# STM32F334x register map
File version: 1.0
Registers are 32-bit, read-write, reset 0x0 unless marked. A register's access mark holds for its fields unless they carry their own. Offsets are from the block's base; [hi:lo] are bit positions; {n}, {i} and the like mark numbered series; 'fields as' and 'values as' point back to an identical list.

## HRTIM_TIMA — High Resolution Timer: TIMA
Base 0x40017480
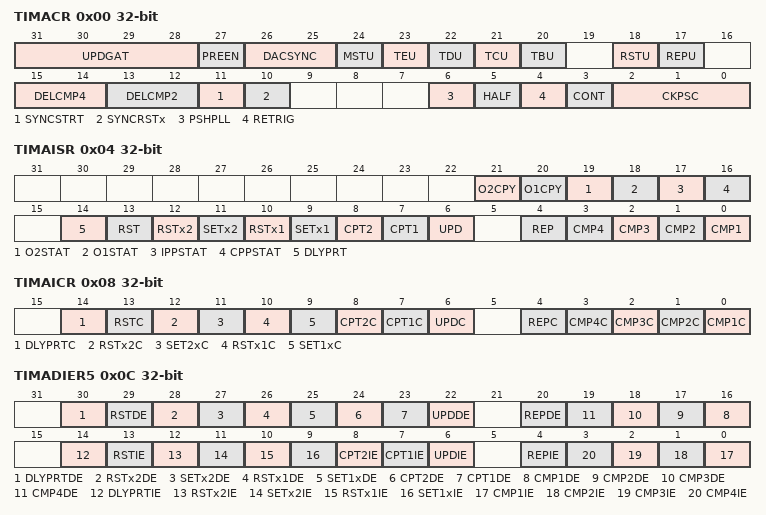
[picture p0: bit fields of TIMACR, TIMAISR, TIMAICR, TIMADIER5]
0x00 TIMACR — Timerx Control Register
  [31:28] UPDGAT — Update Gating
    0=Independent (the update occurs independently from the DMA burst transfer); 1=DMA_Completed (the update occurs when the DMA burst transfer is completed); 2=DMA_Update_Event (the update occurs on the update event following the DMA burst transfer completion); 3=Enable_1 (the update occurs on a rising edge of HRTIM update enable input 1); 4=Enable_2 (the update occurs on a rising edge of HRTIM update enable input 2); 5=Enable_3 (the update occurs on a rising edge of HRTIM update enable input 3); 6=Enable_1_Update_Event (the update occurs on the update event following a rising edge of HRTIM update enable input 1); 7=Enable_2_Update_Event (the update occurs on the update event following a rising edge of HRTIM update enable input 2); 8=Enable_3_Update_Event (the update occurs on the update event following a rising edge of HRTIM update enable input 3)
  [27] PREEN — Preload enable
  [26:25] DACSYNC — DAC Synchronization
    0=None (No update generated); 1=DACtrigOut1 (Update generated on DACtrigOut1); 2=DACtrigOut2 (Update generated on DACtrigOut2); 3=DACtrigOut3 (Update generated on DACtrigOut3)
  [24] MSTU — Master Timer update
  [23] TEU
  [22] TDU
  [21] TCU
  [20] TBU
  [18] RSTU — Timerx reset update
  [17] REPU — Timer x Repetition update
  [15:14] DELCMP4 — CMP4 auto-delayed mode
    0=Always_Active (CMP4 register is always active (standard compare mode)); 1=Capture_2 (CMP4 value is recomputed and is active following a capture 2 event); 2=Capture_2_Or_Compare_1 (CMP4 value is recomputed and is active following a capture 2 event, or is recomputed and active after Compare 1 match (timeout function if capture 2 event is missing)); 3=Capture_2_Or_Compare_3 (CMP4 value is recomputed and is active following a capture event, or is recomputed and active after Compare 3 match (timeout function if capture event is missing))
  [13:12] DELCMP2 — Delayed CMP2 mode
    0=Always_Active (CMP4 register is always active (standard compare mode)); 1=Capture_1 (CMP2 value is recomputed and is active following a capture 1 event); 2=Capture_1_Or_Compare_1 (CMP2 value is recomputed and is active following a capture 1 event, or is recomputed and active after Compare 1 match (timeout function if capture event is missing)); 3=Capture_1_Or_Compare_3 (CMP2 value is recomputed and is active following a capture 1 event, or is recomputed and active after Compare 3 match (timeout function if capture event is missing))
  [11] SYNCSTRT — Synchronization Starts Timer x
  [10] SYNCRSTx — Synchronization Resets Timer x
  [6] PSHPLL — Push-Pull mode enable
  [5] HALF — Half mode enable
  [4] RETRIG — Re-triggerable mode
  [3] CONT — Continuous mode
  [2:0] CKPSC — HRTIM Timer x Clock prescaler
0x04 TIMAISR ro — TimerA Interrupt Status Register
  [21] O2CPY — Output 2 Copy
  [20] O1CPY — Output 1 Copy
  [19] O2STAT — Output 2 State
  [18] O1STAT — Output 1 State
  [17] IPPSTAT — Idle Push Pull Status
  [16] CPPSTAT — Current Push Pull Status
  [14] DLYPRT — Delayed Protection Flag
  [13] RST — Reset Interrupt Flag
  [12] RSTx2 — Output 2 Reset Interrupt Flag
  [11] SETx2 — Output 2 Set Interrupt Flag
  [10] RSTx1 — Output 1 Reset Interrupt Flag
  [9] SETx1 — Output 1 Set Interrupt Flag
  [8] CPT2 — Capture2 Interrupt Flag
  [7] CPT1 — Capture1 Interrupt Flag
  [6] UPD — Update Interrupt Flag
  [4] REP — Repetition Interrupt Flag
  [n-1] CMP{n} (n=1..4) — Compare {n} Interrupt Flag
0x08 TIMAICR wo — Timerx Interrupt Clear Register
  [14] DLYPRTC — Delayed Protection Flag Clear
  [13] RSTC — Reset Interrupt flag Clear
  [12] RSTx2C — Output 2 Reset flag Clear
  [11] SET2xC — Output 2 Set flag Clear
  [10] RSTx1C — Output 1 Reset flag Clear
  [9] SET1xC — Output 1 Set flag Clear
  [8] CPT2C — Capture2 Interrupt flag Clear
  [7] CPT1C — Capture1 Interrupt flag Clear
  [6] UPDC — Update Interrupt flag Clear
  [4] REPC — Repetition Interrupt flag Clear
  [n-1] CMP{n}C (n=1..4) — Compare {n} Interrupt flag Clear
0x0C TIMADIER5 — TIMxDIER5
  [30] DLYPRTDE, [29] RSTDE, [28] RSTx2DE, [27] SETx2DE, [26] RSTx1DE, [25] SET1xDE, [24] CPT2DE, [23] CPT1DE, [22] UPDDE, [20] REPDE, [n+15] CMP{n}DE (n=1..4), [14] DLYPRTIE, [13] RSTIE, [12] RSTx2IE, [11] SETx2IE, [10] RSTx1IE, [9] SET1xIE, [8] CPT2IE, [7] CPT1IE, [6] UPDIE, [4] REPIE, [n-1] CMP{n}IE (n=1..4)
0x10 CNTAR — Timerx Counter Register
  [15:0] CNTx — Timerx Counter value
0x14 PERAR reset 0xFFFF — Timerx Period Register
  [15:0] PERx — Timerx Period value
0x18 REPAR — Timerx Repetition Register
  [7:0] REPx — Timerx Repetition counter value
0x1C CMP1AR — Timerx Compare 1 Register
  [15:0] CMP1x — Timerx Compare 1 value
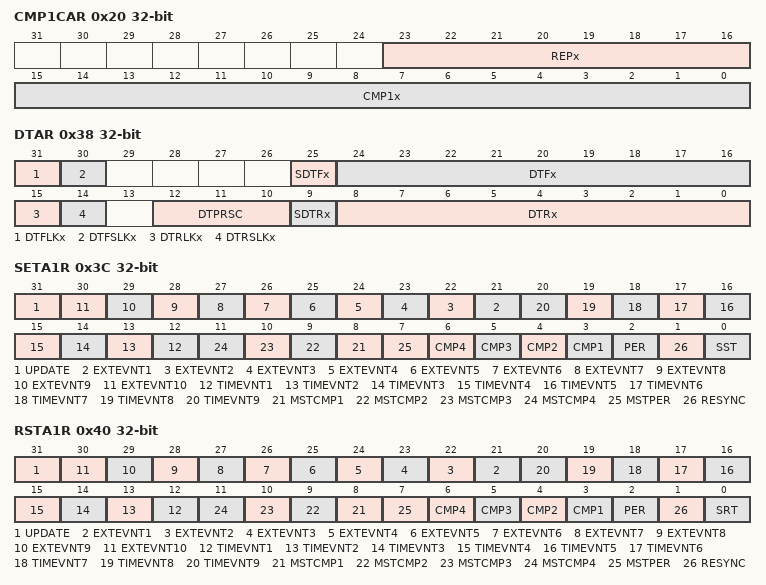
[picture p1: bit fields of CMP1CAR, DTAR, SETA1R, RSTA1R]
0x20 CMP1CAR — Timerx Compare 1 Compound Register
  [23:16] REPx — Timerx Repetition value (aliased from HRTIM_REPx register)
  [15:0] CMP1x — Timerx Compare 1 value
{0x1C+4i} CMP{i}AR (i=2..4) — Timerx Compare {i} Register
  [15:0] CMP{i}x — Timerx Compare {i} value
0x30 CPT1AR ro — Timerx Capture 1 Register
  [15:0] CPT1x — Timerx Capture 1 value
0x34 CPT2AR ro — Timerx Capture 2 Register
  [15:0] CPT2x — Timerx Capture 2 value
0x38 DTAR — Timerx Deadtime Register
  [31] DTFLKx — Deadtime Falling Lock
  [30] DTFSLKx — Deadtime Falling Sign Lock
  [25] SDTFx — Sign Deadtime Falling value
  [24:16] DTFx — Deadtime Falling value
  [15] DTRLKx — Deadtime Rising Lock
  [14] DTRSLKx — Deadtime Rising Sign Lock
  [12:10] DTPRSC — Deadtime Prescaler
  [9] SDTRx — Sign Deadtime Rising value
  [8:0] DTRx — Deadtime Rising value
0x3C SETA1R — Timerx Output1 Set Register
  [31] UPDATE — Registers update (transfer preload to active)
  [n+20] EXTEVNT{n} (n=1..10) — External Event {n}
  [n+11] TIMEVNT{n} (n=1..9) — Timer Event {n}
  [n+7] MSTCMP{n} (n=1..4) — Master Compare {n}
  [7] MSTPER — Master Period
  [n+2] CMP{n} (n=1..4) — Timer A compare {n}
  [2] PER — Timer A Period
  [1] RESYNC — Timer A resynchronizaton
  [0] SST — Software Set trigger
0x40 RSTA1R — Timerx Output1 Reset Register
  [31] UPDATE, [n+20] EXTEVNT{n} (n=1..10), [n+11] TIMEVNT{n} (n=1..9), [n+7] MSTCMP{n} (n=1..4), [7] MSTPER, [n+2] CMP{n} (n=1..4), [2] PER, [1] RESYNC, [0] SRT
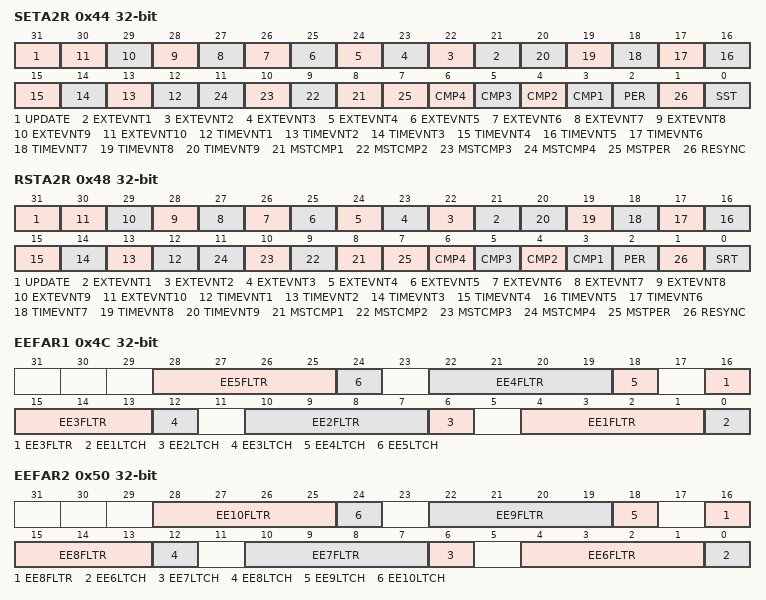
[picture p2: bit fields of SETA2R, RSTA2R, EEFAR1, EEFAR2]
0x44 SETA2R — Timerx Output2 Set Register
  [31] UPDATE, [n+20] EXTEVNT{n} (n=1..10), [n+11] TIMEVNT{n} (n=1..9), [n+7] MSTCMP{n} (n=1..4), [7] MSTPER, [n+2] CMP{n} (n=1..4), [2] PER, [1] RESYNC, [0] SST
0x48 RSTA2R — Timerx Output2 Reset Register
  fields as RSTA1R
0x4C EEFAR1 — Timerx External Event Filtering Register 1
  [6n-2:6n-5] EE{n}FLTR (n=1..5) — External Event {n} filter
    0=No_Filtering; {v}=Blank_Compare_{v} (v=1..4); {v}=Blank_TIMFLTR{v-4} (v=5..12); 13=Window_Compare_2; 14=Window_Compare_3; 15=Window_TIMWIN
  [6n-6] EE{n}LTCH (n=1..5) — External Event {n} latch
0x50 EEFAR2 — Timerx External Event Filtering Register 2
  [6n-32:6n-35] EE{n}FLTR (n=6..10) — External Event {n} filter
    values as EEFAR1.EE1FLTR
  [6n-36] EE{n}LTCH (n=6..10) — External Event {n} latch
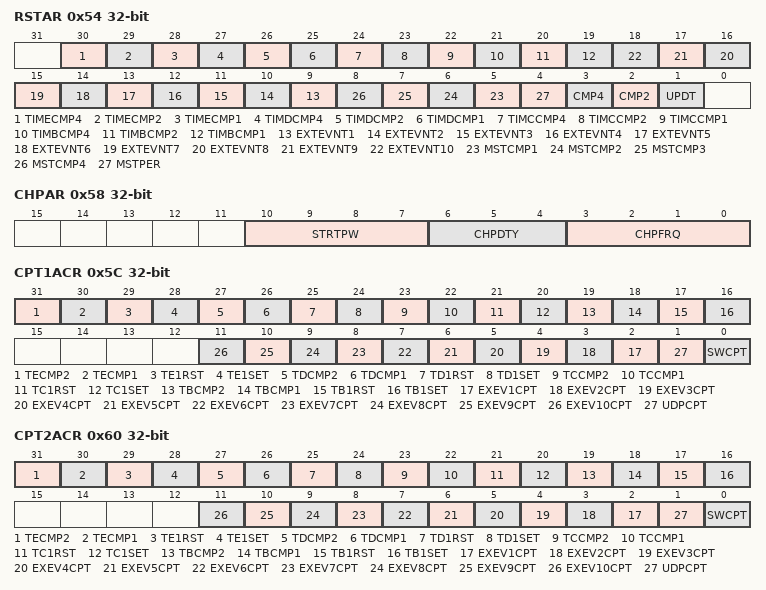
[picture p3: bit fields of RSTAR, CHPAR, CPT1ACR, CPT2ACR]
0x54 RSTAR — TimerA Reset Register
  [30] TIMECMP4 — Timer E Compare 4
  [29] TIMECMP2 — Timer E Compare 2
  [28] TIMECMP1 — Timer E Compare 1
  [27] TIMDCMP4 — Timer D Compare 4
  [26] TIMDCMP2 — Timer D Compare 2
  [25] TIMDCMP1 — Timer D Compare 1
  [24] TIMCCMP4 — Timer C Compare 4
  [23] TIMCCMP2 — Timer C Compare 2
  [22] TIMCCMP1 — Timer C Compare 1
  [21] TIMBCMP4 — Timer B Compare 4
  [20] TIMBCMP2 — Timer B Compare 2
  [19] TIMBCMP1 — Timer B Compare 1
  [n+8] EXTEVNT{n} (n=1..10) — External Event {n}
  [n+4] MSTCMP{n} (n=1..4) — Master compare {n}
  [4] MSTPER — Master timer Period
  [3] CMP4 — Timer A compare 4 reset
  [2] CMP2 — Timer A compare 2 reset
  [1] UPDT — Timer A Update reset
0x58 CHPAR — Timerx Chopper Register
  [10:7] STRTPW
  [6:4] CHPDTY — Timerx chopper duty cycle value
  [3:0] CHPFRQ — Timerx carrier frequency value
0x5C CPT1ACR — Timerx Capture 2 Control Register
  [31] TECMP2 — Timer E Compare 2
  [30] TECMP1 — Timer E Compare 1
  [29] TE1RST — Timer E output 1 Reset
  [28] TE1SET — Timer E output 1 Set
  [27] TDCMP2 — Timer D Compare 2
  [26] TDCMP1 — Timer D Compare 1
  [25] TD1RST — Timer D output 1 Reset
  [24] TD1SET — Timer D output 1 Set
  [23] TCCMP2 — Timer C Compare 2
  [22] TCCMP1 — Timer C Compare 1
  [21] TC1RST — Timer C output 1 Reset
  [20] TC1SET — Timer C output 1 Set
  [19] TBCMP2 — Timer B Compare 2
  [18] TBCMP1 — Timer B Compare 1
  [17] TB1RST — Timer B output 1 Reset
  [16] TB1SET — Timer B output 1 Set
  [n+1] EXEV{n}CPT (n=1..10) — External Event {n} Capture
  [1] UDPCPT — Update Capture
  [0] SWCPT — Software Capture
0x60 CPT2ACR — CPT2xCR
  fields as CPT1ACR
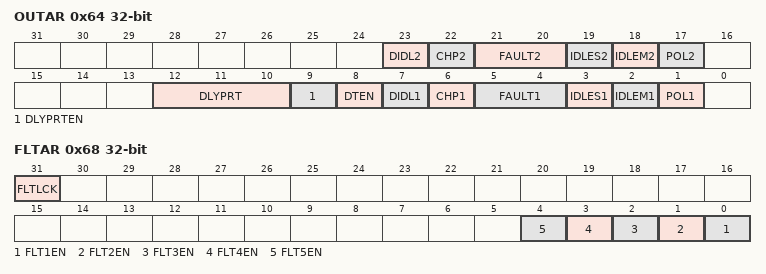
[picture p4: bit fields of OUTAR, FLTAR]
0x64 OUTAR — Timerx Output Register
  [23] DIDL2 — Output 2 Deadtime upon burst mode Idle entry
  [22] CHP2 — Output 2 Chopper enable
  [21:20] FAULT2 — Output 2 Fault state
    0=No action: the output is not affected by the fault input and stays in run mode; 1=Active; 2=Inactive; 3=High_Z
  [19] IDLES2 — Output 2 Idle State
  [18] IDLEM2 — Output 2 Idle mode
  [17] POL2 — Output 2 polarity
  [12:10] DLYPRT — Delayed Protection
  [9] DLYPRTEN — Delayed Protection Enable
  [8] DTEN — Deadtime enable
  [7] DIDL1 — Output 1 Deadtime upon burst mode Idle entry
  [6] CHP1 — Output 1 Chopper enable
  [5:4] FAULT1 — Output 1 Fault state
    values as FAULT2
  [3] IDLES1 — Output 1 Idle State
    0=Inactive; 1=Active
  [2] IDLEM1 — Output 1 Idle mode
  [1] POL1 — Output 1 polarity
    0=Active_High (positive polarity (output active high)); 1=Active_Low (negative polarity (output active low))
0x68 FLTAR — Timerx Fault Register
  [31] FLTLCK — Fault sources Lock
  [n-1] FLT{n}EN (n=1..5) — Fault {n} enable
